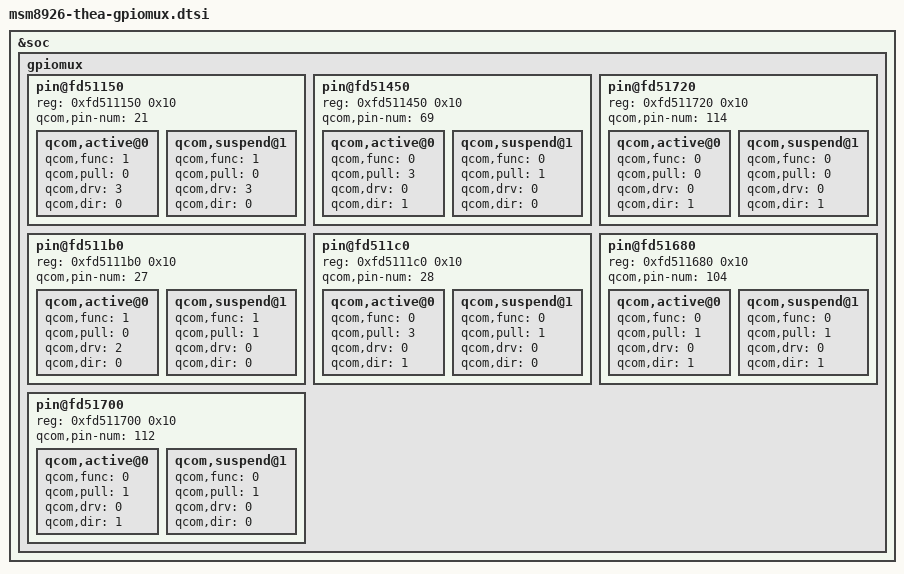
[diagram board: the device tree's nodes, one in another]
/* Copyright (c) 2014, Motorola Mobility LLC. All rights reserved.
 *
 * This program is free software; you can redistribute it and/or modify
 * it under the terms of the GNU General Public License version 2 and
 * only version 2 as published by the Free Software Foundation.
 *
 * This program is distributed in the hope that it will be useful,
 * but WITHOUT ANY WARRANTY; without even the implied warranty of
 * MERCHANTABILITY or FITNESS FOR A PARTICULAR PURPOSE.  See the
 * GNU General Public License for more details.
 */

&soc {
	gpiomux {
		/delete-node/ pin@fd51000; /* Remove GPIO_000 */
		/delete-node/ pin@fd51010; /* Remove GPIO_001 */
		/delete-node/ pin@fd51030; /* Remove GPIO_003 */
		/delete-node/ pin@fd51220; /* Remove GPIO_034 */
		/delete-node/ pin@fd51490; /* Remove GPIO_073 */

		pin@fd51150 {
			reg = <0xfd511150 0x10>;	/* TESTPOINT */
			qcom,pin-num = <21>;
			qcom,active@0 {
				qcom,func = <1>;  /* blsp1_0                */
				qcom,pull = <0>;  /* none                   */
				qcom,drv = <3>;   /* 8ma                    */
				qcom,dir = <0>;   /* input                  */
			};
			qcom,suspend@1 {
				qcom,func = <1>;  /* blsp1_1                */
				qcom,pull = <0>;  /* none                   */
				qcom,drv = <3>;   /* 8ma                    */
				qcom,dir = <0>;   /* input                  */
			};
		};

		pin@fd51450 {
			reg = <0xfd511450  0x10>;	/* TP_AVDD_EN   */
			qcom,pin-num = <69>;
			qcom,active@0 {
				qcom,func = <0>;  /* gpio_in_out(69)        */
				qcom,pull = <3>;  /* pullup                 */
				qcom,drv = <0>;   /* 2ma                    */
				qcom,dir = <1>;   /* output high            */
			};
			qcom,suspend@1 {
				qcom,func = <0>;  /* gpio_in_out(69)        */
				qcom,pull = <1>;  /* down                   */
				qcom,drv = <0>;   /* 2ma                    */
				qcom,dir = <0>;   /* input                  */
			};
		};

		pin@fd51720 {
			reg = <0xfd511720 0x10>;	/* DISP_VDDIO_EN */
			qcom,pin-num = <114>;
			qcom,active@0 {
				qcom,func = <0>;  /* gpio_in_out(114)        */
				qcom,pull = <0>;  /* none                   */
				qcom,drv = <0>;   /* 2ma                    */
				qcom,dir = <1>;   /* output high            */
			};
			qcom,suspend@1 {
				qcom,func = <0>;  /* gpio_in_out(114)        */
				qcom,pull = <0>;  /* none                   */
				qcom,drv = <0>;   /* 2ma                    */
				qcom,dir = <1>;   /* output high            */
			};
		};

		pin@fd511b0 {
			reg = <0xfd5111b0 0x10>;	/* CAM_MCLK1 */
			qcom,pin-num = <27>;
			qcom,active@0 {
				qcom,func = <1>;  /* cam_mclk1              */
				qcom,pull = <0>;  /* none                   */
				qcom,drv = <2>;   /* 6ma                    */
				qcom,dir = <0>;   /* input                  */
			};
			qcom,suspend@1 {
				qcom,func = <1>;  /* cam_mclk1              */
				qcom,pull = <1>;  /* down                   */
				qcom,drv = <0>;   /* 2ma                    */
				qcom,dir = <0>;   /* input                  */
			};
		};

		pin@fd511c0 {
			reg = <0xfd5111c0 0x10>;	/* RCAM_AVDD_EN    */
			qcom,pin-num = <28>;
			qcom,active@0 {
				qcom,func = <0>;  /* gpio_in_out(28)        */
				qcom,pull = <3>;  /* pullup                 */
				qcom,drv = <0>;   /* 2ma                    */
				qcom,dir = <1>;   /* output high            */
			};
			qcom,suspend@1 {
				qcom,func = <0>;  /* gpio_in_out(28)        */
				qcom,pull = <1>;  /* down                   */
				qcom,drv = <0>;   /* 2ma                    */
				qcom,dir = <0>;   /* input                  */
			};
		};

		pin@fd51680 {
			reg = <0xfd511680 0x10>;        /* TOP_AMP_BOOST_BP */
			qcom,pin-num = <104>;
			qcom,active@0 {
				qcom,func = <0>;  /* gpio_in_out(104)       */
				qcom,pull = <1>;  /* down                   */
				qcom,drv = <0>;   /* 2ma                    */
				qcom,dir = <1>;   /* output high            */
			};
			qcom,suspend@1 {
				qcom,func = <0>;  /* gpio_in_out(104)       */
				qcom,pull = <1>;  /* down                   */
				qcom,drv = <0>;   /* 2ma                    */
				qcom,dir = <1>;   /* output high            */
			};
		};

		pin@fd51700 {
			reg = <0xfd511700 0x10>;	/* TOP_AMP_BOOST_EN */
			qcom,pin-num = <112>;
			qcom,active@0 {
				qcom,func = <0>;  /* gpio_in_out(112)       */
				qcom,pull = <1>;  /* down                   */
				qcom,drv = <0>;   /* 2ma                    */
				qcom,dir = <1>;   /* output high            */
			};
			qcom,suspend@1 {
				qcom,func = <0>;  /* gpio_in_out(112)       */
				qcom,pull = <1>;  /* down                   */
				qcom,drv = <0>;   /* 2ma                    */
				qcom,dir = <0>;   /* input                  */
			};
		};
	};
};
